AUTOSAR XML (schema 314)
package /ComponentType
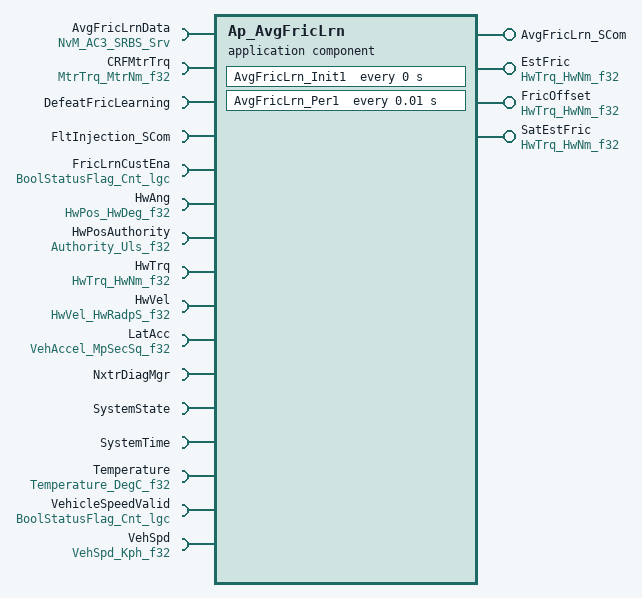
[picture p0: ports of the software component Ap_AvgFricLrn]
  application software component type Ap_AvgFricLrn
    4 x provide port:
      AvgFricLrn_SCom: provided-interface=AvgFricLrn_SCom
        provided-com-specs:
          operation=CaptureOnTheFly, queue-length=1
          operation=GetEOLFric, queue-length=1
          operation=GetOffsetOutputDefeat, queue-length=1
          operation=GetSelect, queue-length=1
          operation=InitLearnedTables, queue-length=1
          operation=ResetToZero, queue-length=1
          operation=SetEOLFric, queue-length=1
          operation=SetOffsetOutputDefeat, queue-length=1
          operation=SetSelect, queue-length=1
      EstFric: unqueued-sender-com-spec{data-element=HwNm_f32, can-invalidate=false, init-value=D_ZERO_ULS_F32}, provided-interface=HwTrq_HwNm_f32
      FricOffset: unqueued-sender-com-spec{data-element=HwNm_f32, can-invalidate=false, init-value=D_ZERO_ULS_F32}, provided-interface=HwTrq_HwNm_f32
      SatEstFric: unqueued-sender-com-spec{data-element=HwNm_f32, can-invalidate=false, init-value=D_ZERO_ULS_F32}, provided-interface=HwTrq_HwNm_f32
    16 x require port:
      AvgFricLrnData: required-com-specs=[EraseBlock, GetErrorStatus, InvalidateNvBlock, ReadBlock, SetRamBlockStatus, WriteBlock], required-interface=NvM_AC3_SRBS_Srv
      CRFMtrTrq: unqueued-receiver-com-spec{data-element=MtrNm_f32, init-value=D_ZERO_ULS_F32}, required-interface=MtrTrq_MtrNm_f32
      DefeatFricLearning: unqueued-receiver-com-spec{data-element=Cnt_lgc, init-value=D_FALSE_CNT_LGC}, required-interface=DefeatFricLearning
      FltInjection_SCom: client-com-spec=FltInjection, required-interface=FltInjection_SCom
      FricLrnCustEna: unqueued-receiver-com-spec{data-element=Cnt_lgc, init-value=D_TRUE_CNT_LGC}, required-interface=BoolStatusFlag_Cnt_lgc
      HwAng: unqueued-receiver-com-spec{data-element=HwDeg_f32, init-value=D_ZERO_ULS_F32}, required-interface=HwPos_HwDeg_f32
      HwPosAuthority: unqueued-receiver-com-spec{data-element=Uls_f32, init-value=D_ZERO_ULS_F32}, required-interface=Authority_Uls_f32
      HwTrq: unqueued-receiver-com-spec{data-element=HwNm_f32, init-value=D_ZERO_ULS_F32}, required-interface=HwTrq_HwNm_f32
      HwVel: unqueued-receiver-com-spec{data-element=HwRadpS_f32, init-value=D_ZERO_ULS_F32}, required-interface=HwVel_HwRadpS_f32
      LatAcc: unqueued-receiver-com-spec{data-element=MpSecSq_f32, init-value=D_ZERO_ULS_F32}, required-interface=VehAccel_MpSecSq_f32
      NxtrDiagMgr: required-com-specs=[GetNTCActive, GetNTCFailed, GetNTCStatus, SetNTCStatus], required-interface=NxtrDiagMgr
      SystemState: required-interface=SystemState
      SystemTime: required-interface=SystemTime
        required-com-specs:
          DtrmnElapsedTime_mS_u16
          DtrmnElapsedTime_mS_u32
          DtrmnElapsedTime_uS_u16
          DtrmnElapsedTime_uS_u32
          GetSystemTime_mS_u32
          GetSystemTime_uS_u32
      Temperature: unqueued-receiver-com-spec{data-element=DegC_f32, init-value=D_ZERO_ULS_F32}, required-interface=Temperature_DegC_f32
      VehicleSpeedValid: unqueued-receiver-com-spec{data-element=Cnt_lgc, init-value=D_FALSE_CNT_LGC}, required-interface=BoolStatusFlag_Cnt_lgc
      VehSpd: unqueued-receiver-com-spec{data-element=Kph_f32, init-value=D_ZERO_ULS_F32}, required-interface=VehSpd_Kph_f32
  internal behavior Ap_AvgFricLrn_InternalBehavior: component=Ap_AvgFricLrn
    timing event AvgFricLrn_Init1_InitEvent: start-on-event=AvgFricLrn_Init1, period=0
    timing event TMT_AvgFricLrn_Per1: mode-dependency=dependent-on-mode=[SystemState.Mode.DISABLE, SystemState.Mode.OFF, SystemState.Mode.WARMINIT], start-on-event=AvgFricLrn_Per1, period=0.01
    8 x operation invoked event:
      OIT_AvgFricLrn_SCom_GetEOLFric_AvgFricLrn_SCom_GetEOLFric: start-on-event=AvgFricLrn_SCom_GetEOLFric, operation=AvgFricLrn_SCom.GetEOLFric
      OIT_AvgFricLrn_SCom_GetOffsetOutputDefeat_AvgFricLrn_SCom_GetOffsetOutputDefeat: start-on-event=AvgFricLrn_SCom_GetOffsetOutputDefeat, operation=AvgFricLrn_SCom.GetOffsetOutputDefeat
      OIT_AvgFricLrn_SCom_GetSelect_AvgFricLrn_SCom_GetSelect: start-on-event=AvgFricLrn_SCom_GetSelect, operation=AvgFricLrn_SCom.GetSelect
      OIT_AvgFricLrn_SCom_InitLearnedTables_AvgFricLrn_SCom_InitLearnedTables: start-on-event=AvgFricLrn_SCom_InitLearnedTables, operation=AvgFricLrn_SCom.InitLearnedTables
      OIT_AvgFricLrn_SCom_ResetToZero_AvgFricLrn_SCom_ResetToZero: start-on-event=AvgFricLrn_SCom_ResetToZero, operation=AvgFricLrn_SCom.ResetToZero
      OIT_AvgFricLrn_SCom_SetEOLFric_AvgFricLrn_SCom_SetEOLFric: start-on-event=AvgFricLrn_SCom_SetEOLFric, operation=AvgFricLrn_SCom.SetEOLFric
      OIT_AvgFricLrn_SCom_SetOffsetOutputDefeat_AvgFricLrn_SCom_SetOffsetOutputDefeat: start-on-event=AvgFricLrn_SCom_SetOffsetOutputDefeat, operation=AvgFricLrn_SCom.SetOffsetOutputDefeat
      OIT_AvgFricLrn_SCom_SetSelect_AvgFricLrn_SCom_SetSelect: start-on-event=AvgFricLrn_SCom_SetSelect, operation=AvgFricLrn_SCom.SetSelect
    mode switch event MST_AvgFricLrn_Trns1_0: start-on-event=AvgFricLrn_Trns1, activation=ENTRY, mode=SystemState.Mode.OFF
    per instance memory AvgFricLrnData: type=AvgFricLrnType, type-definition=/DataType/AvgFricLrnType
    port-api-options:
      enable-take-address=false, indirect-api=false, port=AvgFricLrn_SCom
      enable-take-address=false, indirect-api=false, port=AvgFricLrnData
      enable-take-address=false, indirect-api=false, port=CRFMtrTrq
      enable-take-address=false, indirect-api=false, port=DefeatFricLearning
      enable-take-address=false, indirect-api=false, port=EstFric
      enable-take-address=false, indirect-api=false, port=FltInjection_SCom
      enable-take-address=false, indirect-api=false, port=FricLrnCustEna
      enable-take-address=false, indirect-api=false, port=FricOffset
      enable-take-address=false, indirect-api=false, port=HwAng
      enable-take-address=false, indirect-api=false, port=HwPosAuthority
      enable-take-address=false, indirect-api=false, port=HwTrq
      enable-take-address=false, indirect-api=false, port=HwVel
      enable-take-address=false, indirect-api=false, port=LatAcc
      enable-take-address=false, indirect-api=false, port=NxtrDiagMgr
      enable-take-address=false, indirect-api=false, port=SatEstFric
      enable-take-address=false, indirect-api=false, port=SystemState
      enable-take-address=false, indirect-api=false, port=SystemTime
      enable-take-address=false, indirect-api=false, port=Temperature
      enable-take-address=false, indirect-api=false, port=VehicleSpeedValid
      enable-take-address=false, indirect-api=false, port=VehSpd
    11 x runnable:
      AvgFricLrn_Init1
        data write access WRITE_FricOffset_HwNm_f32: data-element=FricOffset.HwNm_f32
        sync call SC_SystemTime_GetSystemTime_mS_u32: operation=SystemTime.GetSystemTime_mS_u32, timeout=0
      AvgFricLrn_Per1
        11 x data read access:
          READ_CRFMtrTrq_MtrNm_f32: data-element=CRFMtrTrq.MtrNm_f32
          READ_DefeatFricLearning_Cnt_lgc: data-element=DefeatFricLearning.Cnt_lgc
          READ_FricLrnCustEna_Cnt_lgc: data-element=FricLrnCustEna.Cnt_lgc
          READ_HwAng_HwDeg_f32: data-element=HwAng.HwDeg_f32
          READ_HwPosAuthority_Uls_f32: data-element=HwPosAuthority.Uls_f32
          READ_HwTrq_HwNm_f32: data-element=HwTrq.HwNm_f32
          READ_HwVel_HwRadpS_f32: data-element=HwVel.HwRadpS_f32
          READ_LatAcc_MpSecSq_f32: data-element=LatAcc.MpSecSq_f32
          READ_Temperature_DegC_f32: data-element=Temperature.DegC_f32
          READ_VehicleSpeedValid_Cnt_lgc: data-element=VehicleSpeedValid.Cnt_lgc
          READ_VehSpd_Kph_f32: data-element=VehSpd.Kph_f32
        data write access WRITE_EstFric_HwNm_f32: data-element=EstFric.HwNm_f32
        data write access WRITE_FricOffset_HwNm_f32: data-element=FricOffset.HwNm_f32
        data write access WRITE_SatEstFric_HwNm_f32: data-element=SatEstFric.HwNm_f32
        5 x sync call, all with timeout=0:
          SC_AvgFricLrnData_WriteBlock: operation=AvgFricLrnData.WriteBlock
          SC_FltInjection_SCom_FltInjection: operation=FltInjection_SCom.FltInjection
          SC_NxtrDiagMgr_SetNTCStatus: operation=NxtrDiagMgr.SetNTCStatus
          SC_SystemTime_DtrmnElapsedTime_mS_u32: operation=SystemTime.DtrmnElapsedTime_mS_u32
          SC_SystemTime_GetSystemTime_mS_u32: operation=SystemTime.GetSystemTime_mS_u32
      AvgFricLrn_SCom_GetEOLFric
      AvgFricLrn_SCom_GetOffsetOutputDefeat
      AvgFricLrn_SCom_GetSelect
      AvgFricLrn_SCom_InitLearnedTables
      AvgFricLrn_SCom_ResetToZero
      AvgFricLrn_SCom_SetEOLFric
        sync call SC_AvgFricLrnData_WriteBlock: operation=AvgFricLrnData.WriteBlock, timeout=0
      AvgFricLrn_SCom_SetOffsetOutputDefeat
      AvgFricLrn_SCom_SetSelect
        sync call SC_AvgFricLrnData_WriteBlock: operation=AvgFricLrnData.WriteBlock, timeout=0
      AvgFricLrn_Trns1
        sync call SC_AvgFricLrnData_WriteBlock: operation=AvgFricLrnData.WriteBlock, timeout=0
    service-needss:
      swc nv block needs AvgFricLrnBlk: n-data-sets=0, readonly=false, reliability=LOW, resistant-to-changed-sw=false, restore-at-start=false, write-only-once=false, writing-frequency=0, writing-priority=LOW, mirror-block=AvgFricLrnData
  swc implementation Ap_AvgFricLrn_Implementation: behavior=Ap_AvgFricLrn_InternalBehavior
    code-descriptors:
      code Code: type=SRC
